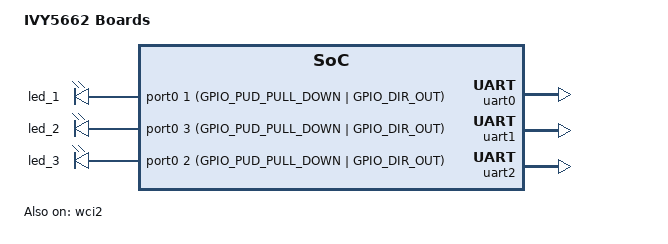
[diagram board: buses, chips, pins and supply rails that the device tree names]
/dts-v1/;

#include <unisoc/uwp5662.dtsi>
#include <dt-bindings/gpio/gpio.h>

/ {
	model = "IVY5662 Boards";
	compatible = "unisoc,uwp5662", "unisoc,uwp566x", "unisoc,uwp";

	chosen {
		zephyr,sram = &sram0;
		zephyr,console = &uart0;
		zephyr,flash = &flash0;
		zephyr,shell-uart = &uart0;
		zephyr,code-partition = &slot0_partition;
	};

	leds {
		compatible = "gpio-leds";
		label = "led";
		led_1 {
			gpios = <&port0 1 (GPIO_PUD_PULL_DOWN | GPIO_DIR_OUT)>;
		};

		led_2 {
			gpios = <&port0 3 (GPIO_PUD_PULL_DOWN | GPIO_DIR_OUT)>;
		};

		led_3 {
			gpios = <&port0 2 (GPIO_PUD_PULL_DOWN | GPIO_DIR_OUT)>;
		};
	};
};

&uart0 {
	status = "ok";
};

&uart1 {
	status = "ok";
};

&uart2 {
	status = "ok";
};

&wci2 {
	status = "ok";
};

&flash0 {
	/*
	 * For more information, see:
	 * http://docs.zephyrproject.org/devices/dts/flash_partitions.html
	 */
	partitions {
		compatible = "fixed-partitions";
		#address-cells = <1>;
		#size-cells = <1>;

		boot_partition: partition@0 {
			label = "mcuboot";
			reg = <0x00000000 DT_SIZE_K(56)>;
		};
		scratch_partition: partition@E000 {
			label = "image-scratch";
			reg = <0x0000E000 DT_SIZE_K(8)>;
		};
		slot0_partition: partition@10000 {
			label = "image-0";
			reg = <0x00010000 DT_SIZE_K(1184)>;
		};
		modem0_partition: partition@D138000 {
			label = "modem-0";
			reg = <0x00138000 DT_SIZE_K(720)>;
		};
		slot1_partition: partition@1EC000 {
			label = "image-1";
			reg = <0x001EC000 DT_SIZE_K(1184)>;
		};
		modem1_partition: partition@314000 {
			label = "modem-1";
			reg = <0x00314000 DT_SIZE_K(720)>;
		};
		hwparam_partition: partition@3C8000 {
			label = "hwparam";
			reg = <0x003C8000 DT_SIZE_K(8)>;
		};

		storage_partition: partition@3CA000 {
			label = "storage";
			reg = <0x0003CA000 DT_SIZE_K(216)>;
		};

	};
};
